# CY8C5868AXI_LP035 register map
File version: 0.1
CY8C58LP
Registers are 8-bit, read-write, no defined reset value unless marked. A register's access mark holds for its fields unless they carry their own. Offsets are from the block's base; lines under a group give offsets from that group; [hi:lo] are bit positions; {n}, {i} and the like mark numbered series; 'fields as' and 'values as' point back to an identical list; <NAME> marks a mode.

## Memory map
0x00000000 PWM_{n} (n=4..11)
0x00000000 Opamp_1
0x00000000 ADC_SAR_1 — SAR ADC
0x00000000 Filter
0x00000000 ADC_SAR_Seq_SAR — SAR ADC
0x00000000 Opamp_2
0x00000000 PWM_ADC_CK
0x4000646B DAC_IN_MSB
0x40006474 DIV_MASK_MSB
0x40006477 DIV_MASK_LSB
0x4000647C ADC_1_OUT_MSB
0x40006564 DAC_IN_LSB
0x40006574 ADC_1_OUT_LSB

## PWM_4
Base 0x00000000
0x40006527 PWM_4_COMPARE_Reg_ — UDB.D0 - Assigned Compare Value
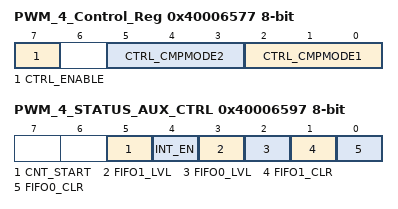
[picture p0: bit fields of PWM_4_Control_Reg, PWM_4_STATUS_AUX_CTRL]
0x40006577 PWM_4_Control_Reg — UDB Control Register - Assigned Control Register Value
  [7] CTRL_ENABLE — Enable the PWM
  [5:3] CTRL_CMPMODE2 — Compare mode 2
  [2:0] CTRL_CMPMODE1 — Compare mode 1
0x40006597 PWM_4_STATUS_AUX_CTRL — UDB Auxilliary Control Register
  [5] CNT_START — FIFO0 clear
    0=E_CNT_START0 (Disable counter); 1=E_CNT_START1 (Enable counter)
  [4] INT_EN
    0=E_INT_EN0 (Interrupt disabled); 1=E_INT_EN1 (Interrupt enabled)
  [3] FIFO1_LVL — FIFO level
    0=E_FIFO_LVL_0 (FIFO LVL: input mode: FIFO not full; output mode: FIFO not empty); 1=E_FIFO_LVL_1 (FIFO LVL: input mode: FIFO at least 1/2 empty; output mode: FIFO at least 1/2 full)
  [2] FIFO0_LVL — FIFO level
    values as FIFO1_LVL
  [1] FIFO1_CLR — FIFO1 clear
    0=E_FIFO_CLR_0 (Normal FIFO operation); 1=E_FIFO_CLR_1 (Clear FIFO state)
  [0] FIFO0_CLR — FIFO0 clear
    values as FIFO1_CLR

## PWM_5
Base 0x00000000
0x40006424 PWM_5_COMPARE_Reg_ — UDB.D0 - Assigned Compare Value
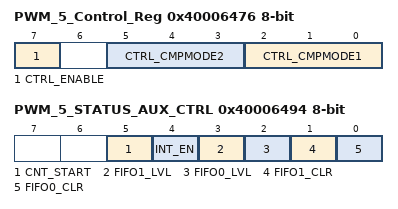
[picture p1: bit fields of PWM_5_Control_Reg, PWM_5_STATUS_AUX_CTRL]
0x40006476 PWM_5_Control_Reg — UDB Control Register - Assigned Control Register Value
  [7] CTRL_ENABLE — Enable the PWM
  [5:3] CTRL_CMPMODE2 — Compare mode 2
  [2:0] CTRL_CMPMODE1 — Compare mode 1
0x40006494 PWM_5_STATUS_AUX_CTRL — UDB Auxilliary Control Register
  [5] CNT_START — FIFO0 clear
    0=E_CNT_START0 (Disable counter); 1=E_CNT_START1 (Enable counter)
  [4] INT_EN
    0=E_INT_EN0 (Interrupt disabled); 1=E_INT_EN1 (Interrupt enabled)
  [3] FIFO1_LVL — FIFO level
    0=E_FIFO_LVL_0 (FIFO LVL: input mode: FIFO not full; output mode: FIFO not empty); 1=E_FIFO_LVL_1 (FIFO LVL: input mode: FIFO at least 1/2 empty; output mode: FIFO at least 1/2 full)
  [2] FIFO0_LVL — FIFO level
    values as FIFO1_LVL
  [1] FIFO1_CLR — FIFO1 clear
    0=E_FIFO_CLR_0 (Normal FIFO operation); 1=E_FIFO_CLR_1 (Clear FIFO state)
  [0] FIFO0_CLR — FIFO0 clear
    values as FIFO1_CLR

## DAC_IN_MSB
Base 0x4000646B
0x00 DAC_IN_MSB_STATUS_REG
0x20 DAC_IN_MSB_MASK_REG
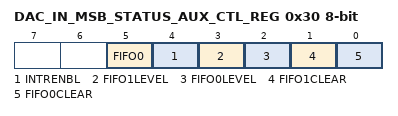
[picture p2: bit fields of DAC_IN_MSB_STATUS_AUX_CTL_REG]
0x30 DAC_IN_MSB_STATUS_AUX_CTL_REG
  [5] FIFO0 — FIFO0 clear
    1=ENABLED (Enable counter); 0=DISABLED (Disable counter)
  [4] INTRENBL — Enables or disables the Interrupt
    1=ENABLED (Interrupt enabled); 0=DISABLED (Interrupt disabled)
  [3] FIFO1LEVEL — FIFO level
    1=ENABLED (FIFO LVL: input mode: FIFO at least 1/2 empty; output mode: FIFO at least 1/2 full); 0=DISABLED (FIFO LVL: input mode: FIFO not full; output mode: FIFO not empty)
  [2] FIFO0LEVEL — FIFO level
    values as FIFO1LEVEL
  [1] FIFO1CLEAR — FIFO clear
    1=ENABLED (Clear FIFO state); 0=DISABLED (Normal FIFO operation)
  [0] FIFO0CLEAR — FIFO clear
    values as FIFO1CLEAR

## DAC_IN_LSB
Base 0x40006564
Registers as DAC_IN_MSB (with DAC_IN_MSB read as DAC_IN_LSB).

## ADC_1_OUT_LSB
Base 0x40006574
0x00 ADC_1_OUT_LSB_CONTROL_REG

## ADC_1_OUT_MSB
Base 0x4000647C
Registers as ADC_1_OUT_LSB (with ADC_1_OUT_LSB read as ADC_1_OUT_MSB).

## DIV_MASK_LSB
Base 0x40006477
Registers as ADC_1_OUT_LSB (with ADC_1_OUT_LSB read as DIV_MASK_LSB).

## DIV_MASK_MSB
Base 0x40006474
Registers as ADC_1_OUT_LSB (with ADC_1_OUT_LSB read as DIV_MASK_MSB).
